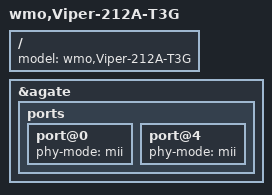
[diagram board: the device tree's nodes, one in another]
#include <coronet/a-cpu.dtsi>

/ {
	model = "wmo,Viper-212A-T3G";
};

&agate {
	ports {
		/* ethX2/3 use two-pair M12 connector */
		port@0 { phy-mode = "mii"; };
		port@4 { phy-mode = "mii"; };
	};
};
